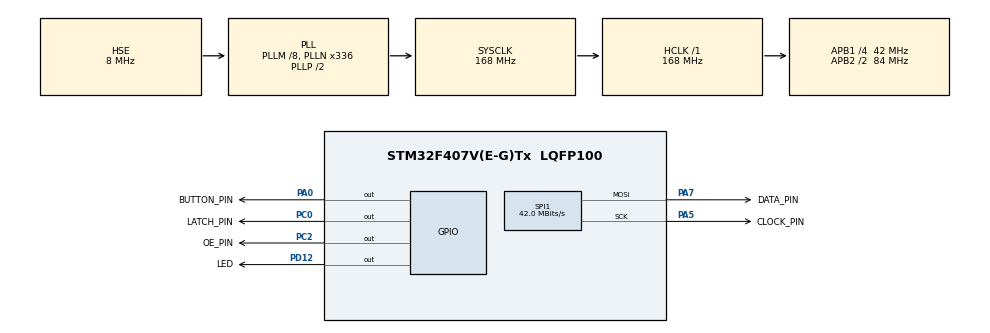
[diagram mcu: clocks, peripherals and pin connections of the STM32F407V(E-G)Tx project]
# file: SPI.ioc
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Mcu.Family=STM32F4
Mcu.Name=STM32F407V(E-G)Tx
Mcu.Package=LQFP100
NVIC.PriorityGroup=NVIC_PRIORITYGROUP_0
PA0-WKUP.GPIO_Label=BUTTON_PIN
PA0-WKUP.Signal=GPIO_Output
PA13.Mode=Serial_Wire
PA13.Signal=SYS_JTMS-SWDIO
PA14.Mode=Serial_Wire
PA14.Signal=SYS_JTCK-SWCLK
PA5.GPIO_Label=CLOCK_PIN
PA5.Mode=TX_Only_Simplex_Unidirect_Master
PA5.Signal=SPI1_SCK
PA7.GPIO_Label=DATA_PIN
PA7.Mode=TX_Only_Simplex_Unidirect_Master
PA7.Signal=SPI1_MOSI
PC0.GPIO_Label=LATCH_PIN
PC0.Signal=GPIO_Output
PC2.GPIO_Label=OE_PIN
PC2.Signal=GPIO_Output
PD12.GPIO_Label=LED
PD12.Signal=GPIO_Output
PH0-OSC_IN.Mode=HSE-External-Oscillator
PH0-OSC_IN.Signal=RCC_OSC_IN
PH1-OSC_OUT.Mode=HSE-External-Oscillator
PH1-OSC_OUT.Signal=RCC_OSC_OUT
ProjectManager.HeapSize=0x200
ProjectManager.StackSize=0x400
ProjectManager.TargetToolchain=MDK-ARM V5
RCC.48MHZClocksFreq_Value=84000000
RCC.AHBFreq_Value=168000000
RCC.APB1CLKDivider=RCC_HCLK_DIV4
RCC.APB1Freq_Value=42000000
RCC.APB1TimFreq_Value=84000000
RCC.APB2CLKDivider=RCC_HCLK_DIV2
RCC.APB2Freq_Value=84000000
RCC.APB2TimFreq_Value=168000000
RCC.CortexFreq_Value=168000000
RCC.HCLKFreq_Value=168000000
RCC.HSE_VALUE=8000000
RCC.HSI_VALUE=16000000
RCC.LSE_VALUE=32768
RCC.PLLM=8
RCC.PLLN=336
RCC.PLLSourceVirtual=RCC_PLLSOURCE_HSE
RCC.SYSCLKFreq_VALUE=168000000
RCC.SYSCLKSource=RCC_SYSCLKSOURCE_PLLCLK
RCC.VCOOutputFreq_Value=336000000
SPI1.CalculateBaudRate=42.0 MBits/s
SPI1.Direction=SPI_DIRECTION_2LINES
SPI1.Mode=SPI_MODE_MASTER
SPI1.VirtualType=VM_MASTER
board=STM32F407G-DISC1

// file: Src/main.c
/* USER CODE BEGIN Header */
/**
  ******************************************************************************
  * @file           : main.c
  * @brief          : Main program body
  ******************************************************************************
  * @attention
  *
  * <h2><center>&copy; Copyright (c) 2020 STMicroelectronics.
  * All rights reserved.</center></h2>
  *
  * This software component is licensed by ST under BSD 3-Clause license,
  * the "License"; You may not use this file except in compliance with the
  * License. You may obtain a copy of the License at:
  *                        opensource.org/licenses/BSD-3-Clause
  *
  ******************************************************************************
  */
/* USER CODE END Header */

#include "main.h"

SPI_HandleTypeDef hspi1;
uint8_t dataOut[1]={0xf0};
//unsigned char array[] = {      0xF0,    0xCC,    0xAA,    0xF0};

void SystemClock_Config(void);
static void MX_GPIO_Init(void);
static void MX_SPI1_Init(void);
void shiftOut(uint8_t * data, uint16_t size);
//void MPSTM_PowerUpShiftReg(bool onOff);

int main(void)
{

  /* MCU Configuration--------------------------------------------------------*/

  /* Reset of all peripherals, Initializes the Flash interface and the Systick. */
  HAL_Init();

  /* Configure the system clock */
  SystemClock_Config();

  /* Initialize all configured peripherals */
  MX_GPIO_Init();
  MX_SPI1_Init();
  /* USER CODE BEGIN 2 */
//	 for(int i=0;i<4;i++)
//		{
//
//			//if (HAL_GPIO_ReadPin(GPIOA, GPIO_PIN_0))
//			//{
//			shiftOut(&dataOut[i],1);
//			//HAL_Delay(50);
//			//}
 for(int i=0;i<1;i++)
		{

			//if (HAL_GPIO_ReadPin(GPIOA, GPIO_PIN_0))
			//{
			shiftOut(&dataOut[i],1);
			//HAL_GPIO_WritePin(GPIOD,GPIO_PIN_12|GPIO_PIN_13|GPIO_PIN_14|GPIO_PIN_15,GPIO_PIN_SET);
			//HAL_Delay(50);
			//}
			//break;

	}

  /* USER CODE END 2 */

  /* Infinite loop */
  while (1)
  {

    /* USER CODE BEGIN 3 */
		//shiftOut(dataOut,1);
//		 for(int i=0;i<2;i++)
//		{
//
//			//if (HAL_GPIO_ReadPin(GPIOA, GPIO_PIN_0))
//			//{
//			shiftOut(&dataOut[i],1);
//			//HAL_GPIO_WritePin(GPIOD,GPIO_PIN_12|GPIO_PIN_13|GPIO_PIN_14|GPIO_PIN_15,GPIO_PIN_SET);
//			//HAL_Delay(50);
//			//}
//
//	}
//
}

	}

  /* USER CODE END 3 */

void SystemClock_Config(void)
{
  RCC_OscInitTypeDef RCC_OscInitStruct = {0};
  RCC_ClkInitTypeDef RCC_ClkInitStruct = {0};

  /** Configure the main internal regulator output voltage
  */
  __HAL_RCC_PWR_CLK_ENABLE();
  __HAL_PWR_VOLTAGESCALING_CONFIG(PWR_REGULATOR_VOLTAGE_SCALE1);
  /** Initializes the CPU, AHB and APB busses clocks
  */
  RCC_OscInitStruct.OscillatorType = RCC_OSCILLATORTYPE_HSE;
  RCC_OscInitStruct.HSEState = RCC_HSE_ON;
  RCC_OscInitStruct.PLL.PLLState = RCC_PLL_ON;
  RCC_OscInitStruct.PLL.PLLSource = RCC_PLLSOURCE_HSE;
  RCC_OscInitStruct.PLL.PLLM = 8;
  RCC_OscInitStruct.PLL.PLLN = 336;
  RCC_OscInitStruct.PLL.PLLP = RCC_PLLP_DIV2;
  RCC_OscInitStruct.PLL.PLLQ = 4;
  if (HAL_RCC_OscConfig(&RCC_OscInitStruct) != HAL_OK)
  {
    Error_Handler();
  }
  /** Initializes the CPU, AHB and APB busses clocks
  */
  RCC_ClkInitStruct.ClockType = RCC_CLOCKTYPE_HCLK|RCC_CLOCKTYPE_SYSCLK
                              |RCC_CLOCKTYPE_PCLK1|RCC_CLOCKTYPE_PCLK2;
  RCC_ClkInitStruct.SYSCLKSource = RCC_SYSCLKSOURCE_PLLCLK;
  RCC_ClkInitStruct.AHBCLKDivider = RCC_SYSCLK_DIV1;
  RCC_ClkInitStruct.APB1CLKDivider = RCC_HCLK_DIV4;
  RCC_ClkInitStruct.APB2CLKDivider = RCC_HCLK_DIV2;

  if (HAL_RCC_ClockConfig(&RCC_ClkInitStruct, FLASH_LATENCY_5) != HAL_OK)
  {
    Error_Handler();
  }
}

static void MX_SPI1_Init(void)
{

  /* SPI1 parameter configuration*/
  hspi1.Instance = SPI1;
  hspi1.Init.Mode = SPI_MODE_MASTER;
  hspi1.Init.Direction = SPI_DIRECTION_2LINES;
  hspi1.Init.DataSize = SPI_DATASIZE_8BIT;
  hspi1.Init.CLKPolarity = SPI_POLARITY_LOW;
  hspi1.Init.CLKPhase = SPI_PHASE_1EDGE;
  hspi1.Init.NSS = SPI_NSS_SOFT;
  hspi1.Init.BaudRatePrescaler = SPI_BAUDRATEPRESCALER_256;
  hspi1.Init.FirstBit = SPI_FIRSTBIT_MSB;
  hspi1.Init.TIMode = SPI_TIMODE_DISABLE;
  hspi1.Init.CRCCalculation = SPI_CRCCALCULATION_DISABLE;
  hspi1.Init.CRCPolynomial = 10;
  if (HAL_SPI_Init(&hspi1) != HAL_OK)
  {
    Error_Handler();
  }

}

static void MX_GPIO_Init(void)
{
  GPIO_InitTypeDef GPIO_InitStruct = {0};

  /* GPIO Ports Clock Enable */
  __HAL_RCC_GPIOH_CLK_ENABLE();
  __HAL_RCC_GPIOC_CLK_ENABLE();
  __HAL_RCC_GPIOA_CLK_ENABLE();
  __HAL_RCC_GPIOD_CLK_ENABLE();

  /*Configure GPIO pin Output Level */
  HAL_GPIO_WritePin(GPIOC, LATCH_PIN_Pin|OE_PIN_Pin, GPIO_PIN_RESET);

  /*Configure GPIO pin Output Level */
  HAL_GPIO_WritePin(BUTTON_PIN_GPIO_Port, BUTTON_PIN_Pin, GPIO_PIN_RESET);

  /*Configure GPIO pin Output Level */
  HAL_GPIO_WritePin(LED_GPIO_Port, LED_Pin, GPIO_PIN_RESET);

  /*Configure GPIO pins : LATCH_PIN_Pin OE_PIN_Pin */
  GPIO_InitStruct.Pin = LATCH_PIN_Pin|OE_PIN_Pin;
  GPIO_InitStruct.Mode = GPIO_MODE_OUTPUT_PP;
  GPIO_InitStruct.Pull = GPIO_NOPULL;
  GPIO_InitStruct.Speed = GPIO_SPEED_FREQ_LOW;
  HAL_GPIO_Init(GPIOC, &GPIO_InitStruct);

  /*Configure GPIO pin : BUTTON_PIN_Pin */
  GPIO_InitStruct.Pin = BUTTON_PIN_Pin;
  GPIO_InitStruct.Mode = GPIO_MODE_OUTPUT_PP;
  GPIO_InitStruct.Pull = GPIO_NOPULL;
  GPIO_InitStruct.Speed = GPIO_SPEED_FREQ_LOW;
  HAL_GPIO_Init(BUTTON_PIN_GPIO_Port, &GPIO_InitStruct);

  /*Configure GPIO pin : LED_Pin */
  GPIO_InitStruct.Pin = LED_Pin;
  GPIO_InitStruct.Mode = GPIO_MODE_OUTPUT_PP;
  GPIO_InitStruct.Pull = GPIO_NOPULL;
  GPIO_InitStruct.Speed = GPIO_SPEED_FREQ_LOW;
  HAL_GPIO_Init(LED_GPIO_Port, &GPIO_InitStruct);

}

/* USER CODE BEGIN 4 */
//void MPSTM_PowerUpShiftReg(bool onOff)
//{
//	if(onOff)
//	{
//		/*ENA Pin set to high*/
//		HAL_GPIO_WritePin(STIM_HS_ENA_GPIO_Port,STIM_HS_ENA_Pin,GPIO_PIN_SET);
//	}else
//	{
//		/*ENA Pin set to low*/
//		HAL_GPIO_WritePin(STIM_HS_ENA_GPIO_Port,STIM_HS_ENA_Pin,GPIO_PIN_RESET);
//	}
//}
void shiftOut(uint8_t * data, uint16_t size)
{
	HAL_GPIO_WritePin(OE_PIN_GPIO_Port,OE_PIN_Pin,GPIO_PIN_RESET);
	HAL_GPIO_WritePin(LATCH_PIN_GPIO_Port,LATCH_PIN_Pin,GPIO_PIN_RESET);
	HAL_SPI_Transmit(&hspi1, data,size,100);
	HAL_GPIO_WritePin(LATCH_PIN_GPIO_Port,LATCH_PIN_Pin,GPIO_PIN_SET);
	//HAL_GPIO_WritePin(OE_PIN_GPIO_Port,OE_PIN_Pin,GPIO_PIN_RESET);
}

/* USER CODE END 4 */

void Error_Handler(void)
{
}

/************************ (C) COPYRIGHT STMicroelectronics *****END OF FILE****/
